# cslr_hpi register map
Vendor: Texas Instruments
Peripheral module from a debugger description file (folder TCI6484_C6457).
Registers are 32-bit, access not given, reset 0x0 unless marked. A register's access mark holds for its fields unless they carry their own. Offsets are as the file gives them; lines under a group give offsets from that group; [hi:lo] are bit positions; {n}, {i} and the like mark numbered series; 'fields as' and 'values as' point back to an identical list; <NAME> marks a mode.

## HPI — Host Port Interface
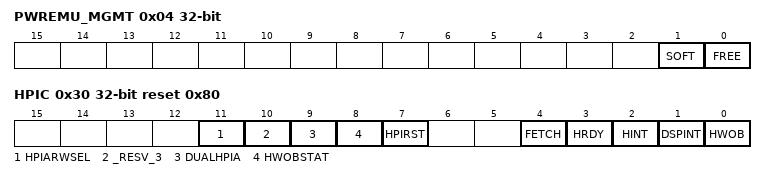
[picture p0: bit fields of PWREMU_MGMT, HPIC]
0x04 PWREMU_MGMT — Power Management and Emulation Register
  [1] SOFT rw — Pheripheral operation not effected
    0=OFF; 1=ON
  [0] FREE rw — If 0 SOFT bit will take effect
    0=OFF; 1=ON
0x30 HPIC reset 0x80 — Host Port Interface Control Register
  [11] HPIARWSEL — HPIA register select bit. When DUAL_HPIA=1, this bit is used to select the HPIA register to be accessed. (access R,RW)
    0=HPIA_R (Select HPIA_R register); 1=HPIA_W (Select HPIA_W register)
  [10] _RESV_3 — (Loop-back mode) Hostless mode is not supported (access N)
  [9] DUALHPIA — Enables dual HPIA mode opeartion. If this bit is 0, the 2 HPIA registers operate as a single virtual HPIA register in terms of host accesses. The CPU can access both HPIA registers separately regardless of DUAL_HPIA setting. R(cntl_mode=0),RW(cntl_mode=1) (access R, RW)
    0=DISABLE (Disable DUAL_HPIA mode); 1=ENABLE (Enable DUAL_HPIA mode)
  [8] HWOBSTAT ro — HWOB status
  [7] HPIRST — The value of HOLD_INIT is stored in this bit upon Vbus reset. When HPI_RST=1, the FIFO pointers are held in reset as soon as pending vbus trancsactions are complete. Even after writing 1 to this bit, the CPU will read back a 0 from this bit until the FIFO (access RW-0 OR 1, R-0)
  [4] FETCH — Host data fetch request bit. Only host can write to this bit. Host and CPU reads of this bit return 0. (access R-0,RW-0)
  [3] HRDY — The logic level of the internal HRDY signal appears in this field. (access R-0, R-1)
  [2] HINT — DSP-to-host interrupt. (access RW,RWC)
    1=DISABLE; 1=ENABLE
  [1] DSPINT — Host-to-DSP interrupt. (access RW,RW)
    0=DISABLE; 1=ENABLE
  [0] HWOB — Half-word Ordering Bit. If HWOB=1, the first half-word is least significant. If HWOB=0, the first half-word is most significant. HWOB must be initialized before the first data or address register access. This bit has no effect in non-multiplexed mode. R(c (access RW,R)
    0=DISABLE; 1=ENABLE
0x34 HPIAW rw — Host Port Interface Address Write Register
  [31:0] HPIAW — HPI Write Address
0x38 HPIAR ro — Host Port Interface Address Read Register
  [31:0] HPIAR — HPI Read Address
